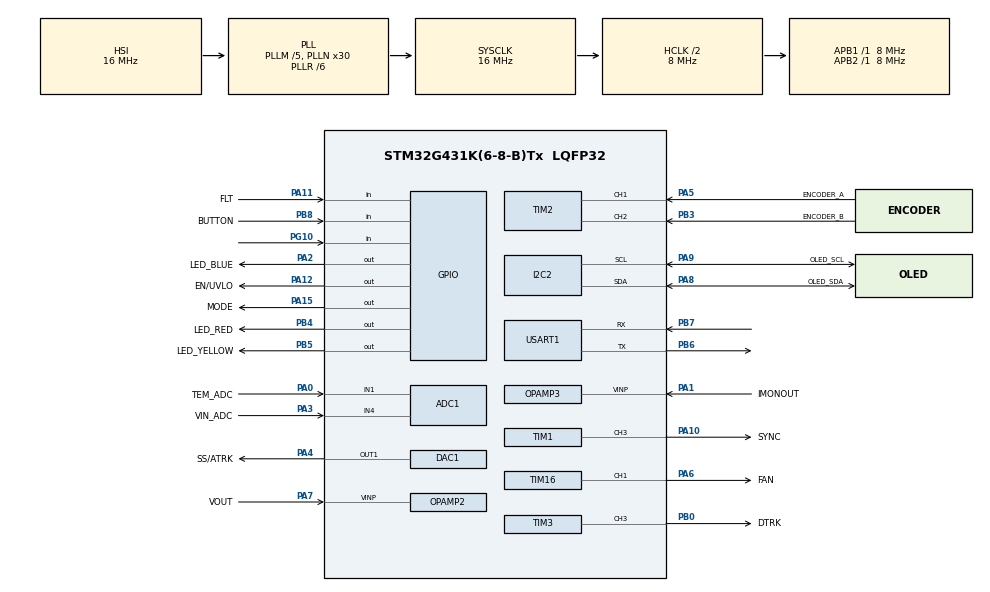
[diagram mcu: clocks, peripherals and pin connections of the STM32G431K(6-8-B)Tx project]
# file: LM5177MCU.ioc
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ADC1.Channel-3\#ChannelRegularConversion=ADC_CHANNEL_1
ADC1.Channel-5\#ChannelRegularConversion=ADC_CHANNEL_4
ADC1.LowPowerAutoWait=DISABLE
ADC1.NbrOfConversion=2
ADC1.NbrOfConversionFlag=1
ADC1.OffsetNumber-3\#ChannelRegularConversion=ADC_OFFSET_NONE
ADC1.OffsetNumber-5\#ChannelRegularConversion=ADC_OFFSET_NONE
ADC1.OversamplingMode=ENABLE
ADC1.Rank-3\#ChannelRegularConversion=1
ADC1.Rank-5\#ChannelRegularConversion=2
ADC1.Ratio=ADC_OVERSAMPLING_RATIO_16
ADC1.RightBitShift=ADC_RIGHTBITSHIFT_4
ADC1.SamplingTime-3\#ChannelRegularConversion=ADC_SAMPLETIME_640CYCLES_5
ADC1.SamplingTime-5\#ChannelRegularConversion=ADC_SAMPLETIME_640CYCLES_5
ADC1.master=1
ADC2.Channel-3\#ChannelRegularConversion=ADC_CHANNEL_VOPAMP2
ADC2.Channel-4\#ChannelRegularConversion=ADC_CHANNEL_VOPAMP3_ADC2
ADC2.NbrOfConversion=2
ADC2.NbrOfConversionFlag=1
ADC2.OffsetNumber-3\#ChannelRegularConversion=ADC_OFFSET_NONE
ADC2.OffsetNumber-4\#ChannelRegularConversion=ADC_OFFSET_NONE
ADC2.OversamplingMode=ENABLE
ADC2.Rank-3\#ChannelRegularConversion=1
ADC2.Rank-4\#ChannelRegularConversion=2
ADC2.Ratio=ADC_OVERSAMPLING_RATIO_16
ADC2.RightBitShift=ADC_RIGHTBITSHIFT_4
ADC2.SamplingTime-3\#ChannelRegularConversion=ADC_SAMPLETIME_640CYCLES_5
ADC2.SamplingTime-4\#ChannelRegularConversion=ADC_SAMPLETIME_640CYCLES_5
I2C2.Timing=0x00201D2B
Mcu.Family=STM32G4
Mcu.Name=STM32G431K(6-8-B)Tx
Mcu.Package=LQFP32
NVIC.PriorityGroup=NVIC_PRIORITYGROUP_4
PA0.GPIO_Label=TEM_ADC
PA0.Mode=IN1-Single-Ended
PA0.Signal=ADC1_IN1
PA1.GPIO_Label=IMONOUT
PA1.Mode=Follower_Internally_Connected
PA1.Signal=OPAMP3_VINP
PA10.GPIO_Label=SYNC
PA10.Signal=S_TIM1_CH3
PA11.GPIO_Label=FLT
PA11.Signal=GPIO_Input
PA12.GPIO_Label=EN/UVLO
PA12.Signal=GPIO_Output
PA13.Mode=Serial_Wire
PA13.Signal=SYS_JTMS-SWDIO
PA14.Mode=Serial_Wire
PA14.Signal=SYS_JTCK-SWCLK
PA15.GPIO_Label=MODE
PA15.Signal=GPIO_Output
PA2.GPIO_Label=LED_BLUE
PA2.Signal=GPIO_Output
PA3.GPIO_Label=VIN_ADC
PA3.Mode=IN4-Single-Ended
PA3.Signal=ADC1_IN4
PA4.GPIO_Label=SS/ATRK
PA4.Signal=COMP_DAC11_group
PA5.GPIO_Label=ENCODER_A
PA5.GPIO_PuPd=GPIO_PULLUP
PA5.GPIO_Pull=GPIO_PULLUP
PA5.Signal=S_TIM2_CH1
PA6.GPIO_Label=FAN
PA6.Signal=S_TIM16_CH1
PA7.GPIO_Label=VOUT
PA7.Mode=Follower_Internally_Connected
PA7.Signal=OPAMP2_VINP
PA8.GPIO_Label=OLED_SDA
PA8.Mode=I2C
PA8.Signal=I2C2_SDA
PA9.GPIO_Label=OLED_SCL
PA9.Mode=I2C
PA9.Signal=I2C2_SCL
PB0.GPIO_Label=DTRK
PB0.GPIO_ModeDefaultPP=GPIO_MODE_AF_PP
PB0.GPIO_PuPd=GPIO_NOPULL
PB0.GPIO_Speed=GPIO_SPEED_FREQ_HIGH
PB0.Signal=S_TIM3_CH3
PB3.GPIO_Label=ENCODER_B
PB3.GPIO_PuPd=GPIO_PULLUP
PB3.GPIO_Pull=GPIO_PULLUP
PB3.Signal=S_TIM2_CH2
PB4.GPIO_Label=LED_RED
PB4.Signal=GPIO_Output
PB5.GPIO_Label=LED_YELLOW
PB5.Signal=GPIO_Output
PB6.Mode=Asynchronous
PB6.Signal=USART1_TX
PB7.Mode=Asynchronous
PB7.Signal=USART1_RX
PB8-BOOT0.GPIO_Label=BUTTON
PB8-BOOT0.Signal=GPIO_Input
PG10-NRST.Signal=GPIO_Input
ProjectManager.HeapSize=0x200
ProjectManager.StackSize=0x400
ProjectManager.TargetToolchain=MDK-ARM V5.32
RCC.ADC12Freq_Value=16000000
RCC.AHBCLKDivider=RCC_SYSCLK_DIV2
RCC.AHBFreq_Value=8000000
RCC.APB1Freq_Value=8000000
RCC.APB1TimFreq_Value=8000000
RCC.APB2Freq_Value=8000000
RCC.APB2TimFreq_Value=8000000
RCC.CortexFreq_Value=8000000
RCC.EXTERNAL_CLOCK_VALUE=12288000
RCC.HCLKFreq_Value=8000000
RCC.HSE_VALUE=25000000
RCC.HSI48_VALUE=48000000
RCC.HSI_VALUE=16000000
RCC.LSE_VALUE=32768
RCC.PLLM=RCC_PLLM_DIV5
RCC.PLLN=30
RCC.PLLR=RCC_PLLR_DIV6
RCC.SYSCLKFreq_VALUE=16000000
RCC.SYSCLKSource=RCC_SYSCLKSOURCE_PLLCLK
RCC.USBFreq_Value=48000000
RCC.VCOOutputFreq_Value=96000000
SH.COMP_DAC11_group.0=DAC1_OUT1,DAC_OUT1
SH.S_TIM16_CH1.0=TIM16_CH1,PWM Generation1 CH1
SH.S_TIM1_CH3.0=TIM1_CH3,PWM Generation3 CH3
SH.S_TIM2_CH1.0=TIM2_CH1,Encoder_Interface
SH.S_TIM2_CH2.0=TIM2_CH2,Encoder_Interface
SH.S_TIM3_CH3.0=TIM3_CH3,PWM Generation3 CH3
TIM1.Channel-PWM\ Generation3\ CH3=TIM_CHANNEL_3
TIM16.Channel=TIM_CHANNEL_1
TIM3.AutoReloadPreload=TIM_AUTORELOAD_PRELOAD_ENABLE
TIM3.Channel-PWM\ Generation3\ CH3=TIM_CHANNEL_3
TIM3.OCPolarity_3=TIM_OCPOLARITY_HIGH
TIM3.PeriodNoDither=31
TIM3.PulseNoDither_3=16
USART1.VirtualMode-Asynchronous=VM_ASYNC
VP_ADC2_OPAMP_INTERNAL2.Mode=IN-OPAMP2
VP_ADC2_OPAMP_INTERNAL3.Mode=IN-OPAMP3
VP_FMAC_VS_FMAC.Mode=FMAC_Activate
VP_SYS_VS_DBSignals.Mode=DisableDeadBatterySignals
VP_TIM16_VS_ClockSourceINT.Mode=Enable_Timer
VP_TIM1_VS_ClockSourceINT.Mode=Internal
VP_TIM3_VS_ClockSourceINT.Mode=Internal
board=custom

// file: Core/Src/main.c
/* USER CODE BEGIN Header */
/**
  ******************************************************************************
  * @file           : main.c
  * @brief          : Main program body
  ******************************************************************************
  * @attention
  *
  * Copyright (c) 2026 STMicroelectronics.
  * All rights reserved.
  *
  * This software is licensed under terms that can be found in the LICENSE file
  * in the root directory of this software component.
  * If no LICENSE file comes with this software, it is provided AS-IS.
  *
  ******************************************************************************
  */
/* USER CODE END Header */
#include "main.h"
#include "adc.h"
#include "dac.h"
#include "fmac.h"
#include "i2c.h"
#include "opamp.h"
#include "tim.h"
#include "usart.h"
#include "gpio.h"

/* USER CODE BEGIN Includes */
#include "app.h"

/* USER CODE END Includes */

void SystemClock_Config(void);

int main(void)
{

  /* MCU Configuration--------------------------------------------------------*/

  /* Reset of all peripherals, Initializes the Flash interface and the Systick. */
  HAL_Init();

  /* Configure the system clock */
  SystemClock_Config();

  /* Initialize all configured peripherals */
  MX_GPIO_Init();
  MX_ADC1_Init();
  MX_I2C2_Init();
  MX_TIM1_Init();
  MX_TIM2_Init();
  MX_TIM3_Init();
  MX_USART1_UART_Init();
  MX_ADC2_Init();
  MX_TIM16_Init();
  MX_FMAC_Init();
  MX_OPAMP3_Init();
  MX_DAC1_Init();
  MX_OPAMP2_Init();
  /* USER CODE BEGIN 2 */

  /* 板级驱动和应用状态统一由 App 层初始化。 */
  if (App_Init() != HAL_OK)
  {
    Error_Handler();
  }

  /* USER CODE END 2 */

  /* Infinite loop */
  /* USER CODE BEGIN WHILE */
  while (1)
  {
    /* 非阻塞执行按键去抖、ADC 采样和状态页刷新。 */
    if (App_Process() != HAL_OK)
    {
      Error_Handler();
    }
    /* USER CODE END WHILE */

  }
}

void SystemClock_Config(void)
{
  RCC_OscInitTypeDef RCC_OscInitStruct = {0};
  RCC_ClkInitTypeDef RCC_ClkInitStruct = {0};

  /** Configure the main internal regulator output voltage
  */
  HAL_PWREx_ControlVoltageScaling(PWR_REGULATOR_VOLTAGE_SCALE1);

  /** Initializes the RCC Oscillators according to the specified parameters
  * in the RCC_OscInitTypeDef structure.
  */
  RCC_OscInitStruct.OscillatorType = RCC_OSCILLATORTYPE_HSI;
  RCC_OscInitStruct.HSIState = RCC_HSI_ON;
  RCC_OscInitStruct.HSICalibrationValue = RCC_HSICALIBRATION_DEFAULT;
  RCC_OscInitStruct.PLL.PLLState = RCC_PLL_ON;
  RCC_OscInitStruct.PLL.PLLSource = RCC_PLLSOURCE_HSI;
  RCC_OscInitStruct.PLL.PLLM = RCC_PLLM_DIV5;
  RCC_OscInitStruct.PLL.PLLN = 30;
  RCC_OscInitStruct.PLL.PLLP = RCC_PLLP_DIV2;
  RCC_OscInitStruct.PLL.PLLQ = RCC_PLLQ_DIV2;
  RCC_OscInitStruct.PLL.PLLR = RCC_PLLR_DIV6;
  if (HAL_RCC_OscConfig(&RCC_OscInitStruct) != HAL_OK)
  {
    Error_Handler();
  }

  /** Initializes the CPU, AHB and APB buses clocks
  */
  RCC_ClkInitStruct.ClockType = RCC_CLOCKTYPE_HCLK|RCC_CLOCKTYPE_SYSCLK
                              |RCC_CLOCKTYPE_PCLK1|RCC_CLOCKTYPE_PCLK2;
  RCC_ClkInitStruct.SYSCLKSource = RCC_SYSCLKSOURCE_PLLCLK;
  RCC_ClkInitStruct.AHBCLKDivider = RCC_SYSCLK_DIV2;
  RCC_ClkInitStruct.APB1CLKDivider = RCC_HCLK_DIV1;
  RCC_ClkInitStruct.APB2CLKDivider = RCC_HCLK_DIV1;

  if (HAL_RCC_ClockConfig(&RCC_ClkInitStruct, FLASH_LATENCY_0) != HAL_OK)
  {
    Error_Handler();
  }
}

void Error_Handler(void)
{
  __disable_irq();
  while (1)
  {
  }
}
